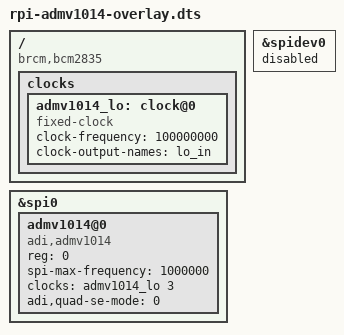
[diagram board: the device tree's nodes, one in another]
/dts-v1/;
/plugin/;

/ {
	compatible = "brcm,bcm2835";

	

	fragment@0 {
		target = <&spidev0>;

		__overlay__ {
			status = "disabled";
		};
	};

	fragment@1 {
		target-path = "/";
		__overlay__ {
			clocks {
				admv1014_lo: clock@0 {
					compatible = "fixed-clock";

					clock-frequency = <100000000>;
					clock-output-names = "lo_in";
					#clock-cells = <1>;
				};
			};
		};
	};

	fragment@2 {
		target = <&spi0>;

		__overlay__{
			#address-cells = <1>;
			#size-cells = <0>;
			status = "okay";

			admv1014@0{
				compatible = "adi,admv1014";
				reg = <0>;
				spi-max-frequency = <1000000>;
				clocks = <&admv1014_lo 3>;
				clock-names = "lo_in";
				adi,quad-se-mode = <0>;
			};
		};
	};
};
